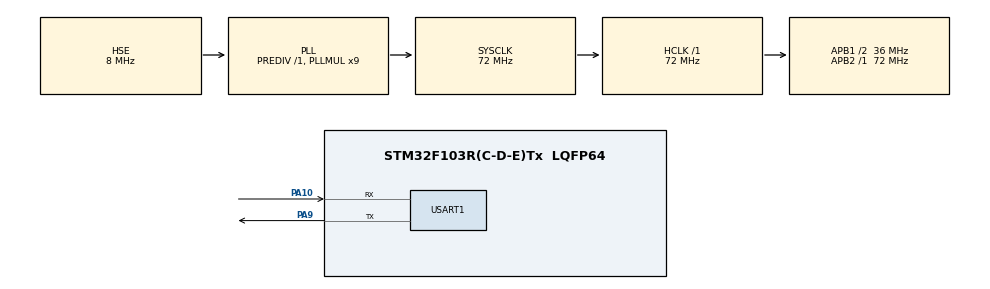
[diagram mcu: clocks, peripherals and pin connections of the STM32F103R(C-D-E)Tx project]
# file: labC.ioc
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FREERTOS.Queues01=myQueue01,4,uint16_t,0,Dynamic,NULL,NULL
FREERTOS.Tasks01=defaultTask,0,128,StartDefaultTask,Default,NULL,Dynamic,NULL,NULL;MsgProduccer,0,128,MsgProducerTask,Default,NULL,Dynamic,NULL,NULL;MsgConsumer,0,128,MsgConsumerTask,Default,NULL,Dynamic,NULL,NULL
Mcu.Family=STM32F1
Mcu.Name=STM32F103R(C-D-E)Tx
Mcu.Package=LQFP64
NVIC.PriorityGroup=NVIC_PRIORITYGROUP_4
NVIC.TIM3_IRQn=true\:0\:0\:false\:false\:true\:false\:false\:true
NVIC.TimeBase=TIM3_IRQn
NVIC.TimeBaseIP=TIM3
NVIC.USART1_IRQn=true\:5\:0\:false\:false\:true\:true\:true\:true
PA10.Mode=Asynchronous
PA10.Signal=USART1_RX
PA13.Mode=Serial_Wire
PA13.Signal=SYS_JTMS-SWDIO
PA14.Mode=Serial_Wire
PA14.Signal=SYS_JTCK-SWCLK
PA9.Mode=Asynchronous
PA9.Signal=USART1_TX
PD0-OSC_IN.Mode=HSE-External-Oscillator
PD0-OSC_IN.Signal=RCC_OSC_IN
PD1-OSC_OUT.Mode=HSE-External-Oscillator
PD1-OSC_OUT.Signal=RCC_OSC_OUT
ProjectManager.HeapSize=0x200
ProjectManager.StackSize=0x400
ProjectManager.TargetToolchain=STM32CubeIDE
RCC.AHBFreq_Value=72000000
RCC.APB1CLKDivider=RCC_HCLK_DIV2
RCC.APB1Freq_Value=36000000
RCC.APB1TimFreq_Value=72000000
RCC.APB2Freq_Value=72000000
RCC.APB2TimFreq_Value=72000000
RCC.HCLKFreq_Value=72000000
RCC.PLLMUL=RCC_PLL_MUL9
RCC.PLLSourceVirtual=RCC_PLLSOURCE_HSE
RCC.SYSCLKFreq_VALUE=72000000
RCC.SYSCLKSource=RCC_SYSCLKSOURCE_PLLCLK
RCC.USBFreq_Value=72000000
USART1.VirtualMode=VM_ASYNC
VP_FREERTOS_VS_CMSIS_V1.Mode=CMSIS_V1
VP_SYS_VS_tim3.Mode=TIM3
board=custom

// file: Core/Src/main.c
/* USER CODE BEGIN Header */
/**
  ******************************************************************************
  * @file           : main.c
  * @brief          : Main program body
  ******************************************************************************
  * @attention
  *
  * <h2><center>&copy; Copyright (c) 2020 STMicroelectronics.
  * All rights reserved.</center></h2>
  *
  * This software component is licensed by ST under BSD 3-Clause license,
  * the "License"; You may not use this file except in compliance with the
  * License. You may obtain a copy of the License at:
  *                        opensource.org/licenses/BSD-3-Clause
  *
  ******************************************************************************
  */
/* USER CODE END Header */

#include "main.h"
#include "cmsis_os.h"
#include "usart.h"
#include "gpio.h"

void SystemClock_Config(void);
void MX_FREERTOS_Init(void);

int main(void)
{

  /* MCU Configuration--------------------------------------------------------*/

  /* Reset of all peripherals, Initializes the Flash interface and the Systick. */
  HAL_Init();

  /* Configure the system clock */
  SystemClock_Config();

  /* Initialize all configured peripherals */
  MX_GPIO_Init();
  MX_USART1_UART_Init();

  /* Call init function for freertos objects (in freertos.c) */
  MX_FREERTOS_Init();
  /* Start scheduler */
  osKernelStart();

  /* We should never get here as control is now taken by the scheduler */
  /* Infinite loop */
  while (1)
  {

  }
}

void SystemClock_Config(void)
{
  RCC_OscInitTypeDef RCC_OscInitStruct = {0};
  RCC_ClkInitTypeDef RCC_ClkInitStruct = {0};

  /** Initializes the CPU, AHB and APB busses clocks
  */
  RCC_OscInitStruct.OscillatorType = RCC_OSCILLATORTYPE_HSE;
  RCC_OscInitStruct.HSEState = RCC_HSE_ON;
  RCC_OscInitStruct.HSEPredivValue = RCC_HSE_PREDIV_DIV1;
  RCC_OscInitStruct.HSIState = RCC_HSI_ON;
  RCC_OscInitStruct.PLL.PLLState = RCC_PLL_ON;
  RCC_OscInitStruct.PLL.PLLSource = RCC_PLLSOURCE_HSE;
  RCC_OscInitStruct.PLL.PLLMUL = RCC_PLL_MUL9;
  if (HAL_RCC_OscConfig(&RCC_OscInitStruct) != HAL_OK)
  {
    Error_Handler();
  }
  /** Initializes the CPU, AHB and APB busses clocks
  */
  RCC_ClkInitStruct.ClockType = RCC_CLOCKTYPE_HCLK|RCC_CLOCKTYPE_SYSCLK
                              |RCC_CLOCKTYPE_PCLK1|RCC_CLOCKTYPE_PCLK2;
  RCC_ClkInitStruct.SYSCLKSource = RCC_SYSCLKSOURCE_PLLCLK;
  RCC_ClkInitStruct.AHBCLKDivider = RCC_SYSCLK_DIV1;
  RCC_ClkInitStruct.APB1CLKDivider = RCC_HCLK_DIV2;
  RCC_ClkInitStruct.APB2CLKDivider = RCC_HCLK_DIV1;

  if (HAL_RCC_ClockConfig(&RCC_ClkInitStruct, FLASH_LATENCY_2) != HAL_OK)
  {
    Error_Handler();
  }
}

 /**
  * @brief  Period elapsed callback in non blocking mode
  * @note   This function is called  when TIM3 interrupt took place, inside
  * HAL_TIM_IRQHandler(). It makes a direct call to HAL_IncTick() to increment
  * a global variable "uwTick" used as application time base.
  * @param  htim : TIM handle
  * @retval None
  */
void HAL_TIM_PeriodElapsedCallback(TIM_HandleTypeDef *htim)
{
  if (htim->Instance == TIM3) {
    HAL_IncTick();
  }
}

void Error_Handler(void)
{
}

/************************ (C) COPYRIGHT STMicroelectronics *****END OF FILE****/

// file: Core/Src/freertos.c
/* USER CODE BEGIN Header */
/**
  ******************************************************************************
  * File Name          : freertos.c
  * Description        : Code for freertos applications
  ******************************************************************************
  * @attention
  *
  * <h2><center>&copy; Copyright (c) 2020 STMicroelectronics.
  * All rights reserved.</center></h2>
  *
  * This software component is licensed by ST under Ultimate Liberty license
  * SLA0044, the "License"; You may not use this file except in compliance with
  * the License. You may obtain a copy of the License at:
  *                             www.st.com/SLA0044
  *
  ******************************************************************************
  */
/* USER CODE END Header */

#include "FreeRTOS.h"
#include "task.h"
#include "main.h"
#include "cmsis_os.h"

/* USER CODE BEGIN Includes */
#include "usart.h"
/* USER CODE END Includes */

/* USER CODE BEGIN Variables */
typedef struct
{
	uint16_t var;
} mailStruct;
osMailQId mail01Handle;
/* USER CODE END Variables */
osThreadId defaultTaskHandle;
osThreadId MsgProduccerHandle;
osThreadId MsgConsumerHandle;
osMessageQId myQueue01Handle;

void StartDefaultTask(void const * argument);
void MsgProducerTask(void const * argument);
void MsgConsumerTask(void const * argument);

void MX_FREERTOS_Init(void); /* (MISRA C 2004 rule 8.1) */

/* GetIdleTaskMemory prototype (linked to static allocation support) */
void vApplicationGetIdleTaskMemory( StaticTask_t **ppxIdleTaskTCBBuffer, StackType_t **ppxIdleTaskStackBuffer, uint32_t *pulIdleTaskStackSize );

/* USER CODE BEGIN GET_IDLE_TASK_MEMORY */
static StaticTask_t xIdleTaskTCBBuffer;
static StackType_t xIdleStack[configMINIMAL_STACK_SIZE];

void vApplicationGetIdleTaskMemory( StaticTask_t **ppxIdleTaskTCBBuffer, StackType_t **ppxIdleTaskStackBuffer, uint32_t *pulIdleTaskStackSize )
{
  *ppxIdleTaskTCBBuffer = &xIdleTaskTCBBuffer;
  *ppxIdleTaskStackBuffer = &xIdleStack[0];
  *pulIdleTaskStackSize = configMINIMAL_STACK_SIZE;
  /* place for user code */
}
/* USER CODE END GET_IDLE_TASK_MEMORY */

void MX_FREERTOS_Init(void) {

  /* Create the queue(s) */
  /* definition and creation of myQueue01 */
  osMessageQDef(myQueue01, 4, uint16_t);
  myQueue01Handle = osMessageCreate(osMessageQ(myQueue01), NULL);

  /* USER CODE BEGIN RTOS_QUEUES */
  /* add queues, ... */
  osMailQDef(mail01, 4, mailStruct);
  mail01Handle = osMailCreate(osMailQ(mail01), NULL);
  /* USER CODE END RTOS_QUEUES */

  /* Create the thread(s) */
  /* definition and creation of defaultTask */
  osThreadDef(defaultTask, StartDefaultTask, osPriorityNormal, 0, 128);
  defaultTaskHandle = osThreadCreate(osThread(defaultTask), NULL);

  /* definition and creation of MsgProduccer */
  osThreadDef(MsgProduccer, MsgProducerTask, osPriorityNormal, 0, 128);
  MsgProduccerHandle = osThreadCreate(osThread(MsgProduccer), NULL);

  /* definition and creation of MsgConsumer */
  osThreadDef(MsgConsumer, MsgConsumerTask, osPriorityNormal, 0, 128);
  MsgConsumerHandle = osThreadCreate(osThread(MsgConsumer), NULL);

}

void StartDefaultTask(void const * argument)
{
  for(;;)
  {
    osDelay(1);
  }
}

void MsgProducerTask(void const * argument)
{
  /* USER CODE BEGIN MsgProducerTask */
	mailStruct * mail;
	int var = 0;
	char msg[50];
	/* Infinite loop */
	for(;;)
	{
		osDelay(500);
		mail = (mailStruct *)osMailAlloc(mail01Handle, osWaitForever);
		if(mail != NULL){
			mail->var = var;
			int re = osMailPut(mail01Handle, mail);
			var++;
			sprintf(msg, "Producer value: %d, status:%d\r\n", var, re);
			HAL_UART_Transmit(&huart1, (uint8_t*)msg, strlen(msg), HAL_MAX_DELAY);
		}
//		osDelay(400);
//		mail = (mailStruct *)osMailAlloc(mail01Handle, osWaitForever);
//		mail->var = 2;
//		osMailPut(mail01Handle, mail);
	}
  /* USER CODE END MsgProducerTask */
}

void MsgConsumerTask(void const * argument)
{
  /* USER CODE BEGIN MsgConsumerTask */
	osEvent event;
	mailStruct * pMail;
	char msg[20];
	/* Infinite loop */
	for(;;)
	{
		event = osMailGet(mail01Handle, osWaitForever);
		if (event.status == osEventMail)
		{
			osDelay(700);
			pMail = event.value.p;
			sprintf(msg, "--Consumer value: %d\r\n", pMail->var);
			HAL_UART_Transmit(&huart1, (uint8_t*)msg, strlen(msg), HAL_MAX_DELAY);
			osMailFree(mail01Handle, pMail);
		}
	}
  /* USER CODE END MsgConsumerTask */
}

/************************ (C) COPYRIGHT STMicroelectronics *****END OF FILE****/
